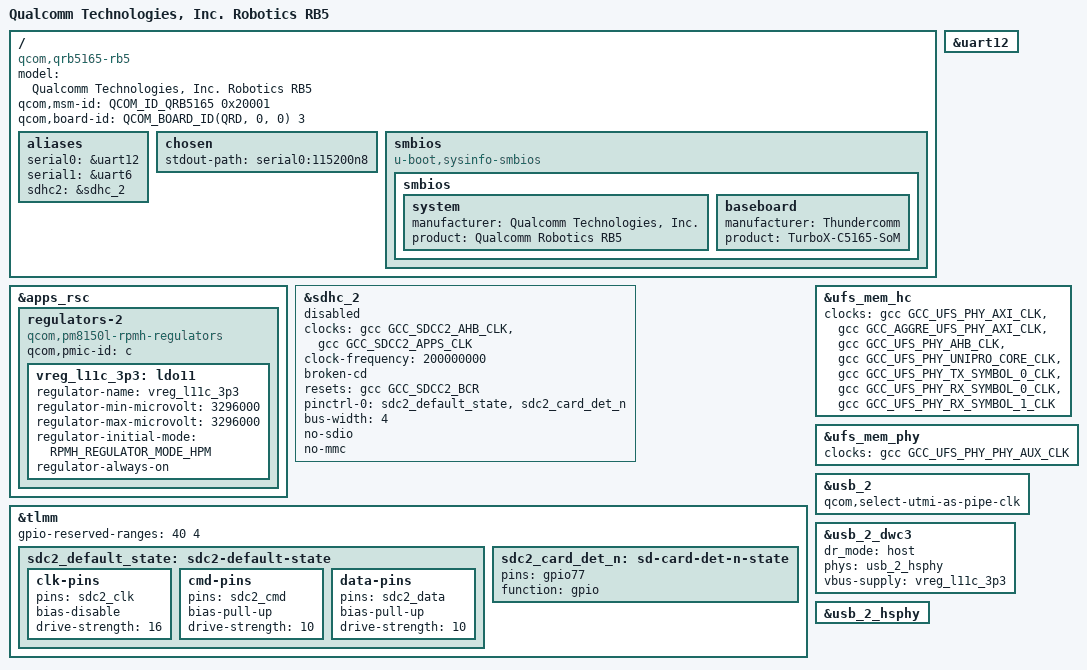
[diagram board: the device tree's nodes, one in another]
// SPDX-License-Identifier: BSD-3-Clause
/*
 * Copyright (c) 2023, Linaro Ltd.
 */

/dts-v1/;

#include <dt-bindings/arm/qcom,ids.h>
#include <dt-bindings/regulator/qcom,rpmh-regulator.h>

#include "sm8250.dtsi"

/ {
	model = "Qualcomm Technologies, Inc. Robotics RB5";
	compatible = "qcom,qrb5165-rb5", "qcom,qrb5165", "qcom,sm8250";
	qcom,msm-id = <QCOM_ID_QRB5165 0x20001>;
	qcom,board-id = <QCOM_BOARD_ID(QRD, 0, 0) 3>;

	aliases {
		serial0 = &uart12;
		serial1 = &uart6;
		sdhc2 = &sdhc_2;
	};

	chosen {
		stdout-path = "serial0:115200n8";
	};

	smbios {
		compatible = "u-boot,sysinfo-smbios";

		smbios {
			system {
				manufacturer = "Qualcomm Technologies, Inc.";
				product = "Qualcomm Robotics RB5";
			};

			baseboard {
				manufacturer = "Thundercomm";
				product = "TurboX-C5165-SoM";
			};
		};
	};
};

&apps_rsc {
	regulators-2 {
		compatible = "qcom,pm8150l-rpmh-regulators";
		qcom,pmic-id = "c";

		vreg_l11c_3p3: ldo11 {
			regulator-name = "vreg_l11c_3p3";
			regulator-min-microvolt = <3296000>;
			regulator-max-microvolt = <3296000>;
			regulator-initial-mode = <RPMH_REGULATOR_MODE_HPM>;
			regulator-always-on;
		};
	};
};

&sdhc_2 {
	/* SD card support is broken currently */
	status = "disabled";

	/* We don't support rpmhcc in u-boot */
	clocks = <&gcc GCC_SDCC2_AHB_CLK>,
		 <&gcc GCC_SDCC2_APPS_CLK>;
	clock-names = "iface", "core";

	clock-frequency = <200000000>;

	//cd-gpios = <&tlmm 77 GPIO_ACTIVE_LOW>;
	broken-cd;

	resets = <&gcc GCC_SDCC2_BCR>;

	pinctrl-0 = <&sdc2_default_state &sdc2_card_det_n>;
	pinctrl-names = "default";

	bus-width = <4>;
	no-sdio;
	no-mmc;
};

&tlmm {
	gpio-reserved-ranges = <40 4>;
};

&uart12 {
	status = "okay";
};

&ufs_mem_hc {
	status = "okay";

	clocks =
		<&gcc GCC_UFS_PHY_AXI_CLK>,
		<&gcc GCC_AGGRE_UFS_PHY_AXI_CLK>,
		<&gcc GCC_UFS_PHY_AHB_CLK>,
		<&gcc GCC_UFS_PHY_UNIPRO_CORE_CLK>,
		<&gcc GCC_UFS_PHY_TX_SYMBOL_0_CLK>,
		<&gcc GCC_UFS_PHY_RX_SYMBOL_0_CLK>,
		<&gcc GCC_UFS_PHY_RX_SYMBOL_1_CLK>;
	clock-names =
		"core_clk",
		"bus_aggr_clk",
		"iface_clk",
		"core_clk_unipro",
		"tx_lane0_sync_clk",
		"rx_lane0_sync_clk",
		"rx_lane1_sync_clk";
};

&ufs_mem_phy {
	status = "okay";

	clocks = <&gcc GCC_UFS_PHY_PHY_AUX_CLK>;
	clock-names = "ref_aux";
};

&usb_2 {
	status = "okay";
	qcom,select-utmi-as-pipe-clk;
};

&usb_2_dwc3 {
	dr_mode = "host";

	phys = <&usb_2_hsphy>;
	phy-names = "usb2-phy";

	vbus-supply = <&vreg_l11c_3p3>;
};

&usb_2_hsphy {
	/* We don't support rpmhcc in u-boot */
	/delete-property/ clocks;
	/delete-property/ clock-names;
	status = "okay";
};

&tlmm {
	sdc2_default_state: sdc2-default-state {
		clk-pins {
			pins = "sdc2_clk";
			bias-disable;
			drive-strength = <16>;
		};

		cmd-pins {
			pins = "sdc2_cmd";
			bias-pull-up;
			drive-strength = <10>;
		};

		data-pins {
			pins = "sdc2_data";
			bias-pull-up;
			drive-strength = <10>;
		};
	};

	sdc2_card_det_n: sd-card-det-n-state {
		pins = "gpio77";
		function = "gpio";
	};
};
